# ATSAM4S4A register map
Vendor: Atmel; File version: 0
CPU: CM4 r0p1, selectable endian, no MPU, no FPU, 0x4 interrupt priority bits, 0x0 interrupts
Registers are 32-bit, read-write, reset 0x0 unless marked. A register's access mark holds for its fields unless they carry their own. Offsets are from the block's base; [hi:lo] are bit positions; {n}, {i} and the like mark numbered series; 'fields as' and 'values as' point back to an identical list.

## PWM — Pulse Width Modulation Controller
Base 0x40020000; register names take the prefix PWM_
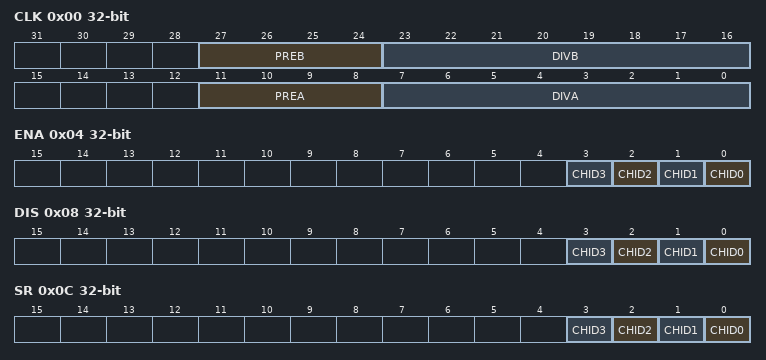
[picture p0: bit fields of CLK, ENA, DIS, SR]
0x00 CLK — PWM Clock Register
  [27:24] PREB — CLKB Source Clock Selection
    0=CLK (Peripheral clock); 1=CLK_DIV2 (Peripheral clock/2); 2=CLK_DIV4 (Peripheral clock/4); 3=CLK_DIV8 (Peripheral clock/8); 4=CLK_DIV16 (Peripheral clock/16); 5=CLK_DIV32 (Peripheral clock/32); 6=CLK_DIV64 (Peripheral clock/64); 7=CLK_DIV128 (Peripheral clock/128); 8=CLK_DIV256 (Peripheral clock/256); 9=CLK_DIV512 (Peripheral clock/512); 10=CLK_DIV1024 (Peripheral clock/1024)
  [23:16] DIVB — CLKB Divide Factor
    0=CLKB_POFF (CLKB clock is turned off); 1=PREB (CLKB clock is clock selected by PREB)
  [11:8] PREA — CLKA Source Clock Selection
    values as PREB
  [7:0] DIVA — CLKA Divide Factor
    0=CLKA_POFF (CLKA clock is turned off); 1=PREA (CLKA clock is clock selected by PREA)
0x04 ENA wo reset not defined — PWM Enable Register
  [n] CHID{n} (n=0..3) — Channel ID
0x08 DIS wo reset not defined — PWM Disable Register
  [n] CHID{n} (n=0..3) — Channel ID
0x0C SR ro — PWM Status Register
  [n] CHID{n} (n=0..3) — Channel ID
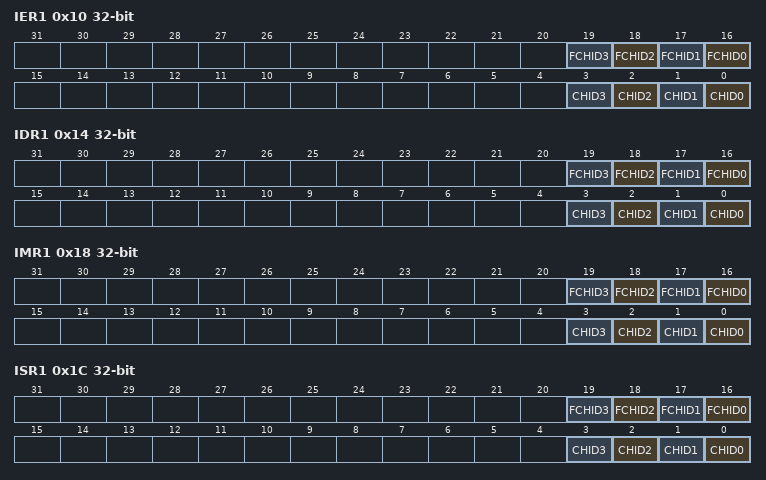
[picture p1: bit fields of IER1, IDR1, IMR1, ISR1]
0x10 IER1 wo reset not defined — PWM Interrupt Enable Register 1
  [n+16] FCHID{n} (n=0..3) — Fault Protection Trigger on Channel {n} Interrupt Enable
  [n] CHID{n} (n=0..3) — Counter Event on Channel {n} Interrupt Enable
0x14 IDR1 wo reset not defined — PWM Interrupt Disable Register 1
  [n+16] FCHID{n} (n=0..3) — Fault Protection Trigger on Channel {n} Interrupt Disable
  [n] CHID{n} (n=0..3) — Counter Event on Channel {n} Interrupt Disable
0x18 IMR1 ro — PWM Interrupt Mask Register 1
  [n+16] FCHID{n} (n=0..3) — Fault Protection Trigger on Channel {n} Interrupt Mask
  [n] CHID{n} (n=0..3) — Counter Event on Channel {n} Interrupt Mask
0x1C ISR1 ro — PWM Interrupt Status Register 1
  [n+16] FCHID{n} (n=0..3) — Fault Protection Trigger on Channel {n}
  [n] CHID{n} (n=0..3) — Counter Event on Channel {n}
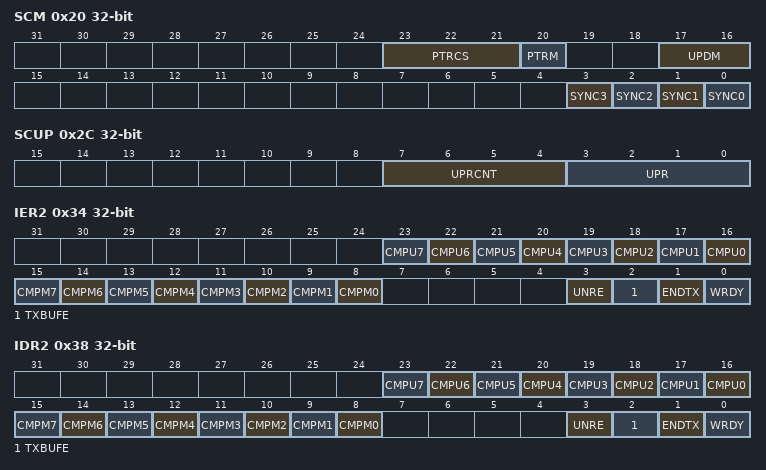
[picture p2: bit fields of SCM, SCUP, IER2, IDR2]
0x20 SCM — PWM Sync Channels Mode Register
  [23:21] PTRCS — Peripheral DMA Controller Transfer Request Comparison Selection
  [20] PTRM — Peripheral DMA Controller Transfer Request Mode
  [17:16] UPDM — Synchronous Channels Update Mode
    0=MODE0 (Manual write of double buffer registers and manual update of synchronous channels); 1=MODE1 (Manual write of double buffer registers and automatic update of synchronous channels); 2=MODE2 (Automatic write of duty-cycle update registers by the Peripheral DMA Controller and automatic update of synchronous channels)
  [n] SYNC{n} (n=0..3) — Synchronous Channel {n}
0x28 SCUC — PWM Sync Channels Update Control Register
  [0] UPDULOCK — Synchronous Channels Update Unlock
0x2C SCUP — PWM Sync Channels Update Period Register
  [7:4] UPRCNT — Update Period Counter
  [3:0] UPR — Update Period
0x30 SCUPUPD wo reset not defined — PWM Sync Channels Update Period Update Register
  [3:0] UPRUPD — Update Period Update
0x34 IER2 wo reset not defined — PWM Interrupt Enable Register 2
  [n+16] CMPU{n} (n=0..7) — Comparison {n} Update Interrupt Enable
  [n+8] CMPM{n} (n=0..7) — Comparison {n} Match Interrupt Enable
  [3] UNRE — Synchronous Channels Update Underrun Error Interrupt Enable
  [2] TXBUFE — PDC TX Buffer Empty Interrupt Enable
  [1] ENDTX — PDC End of TX Buffer Interrupt Enable
  [0] WRDY — Write Ready for Synchronous Channels Update Interrupt Enable
0x38 IDR2 wo reset not defined — PWM Interrupt Disable Register 2
  [n+16] CMPU{n} (n=0..7) — Comparison {n} Update Interrupt Disable
  [n+8] CMPM{n} (n=0..7) — Comparison {n} Match Interrupt Disable
  [3] UNRE — Synchronous Channels Update Underrun Error Interrupt Disable
  [2] TXBUFE — PDC TX Buffer Empty Interrupt Disable
  [1] ENDTX — PDC End of TX Buffer Interrupt Disable
  [0] WRDY — Write Ready for Synchronous Channels Update Interrupt Disable
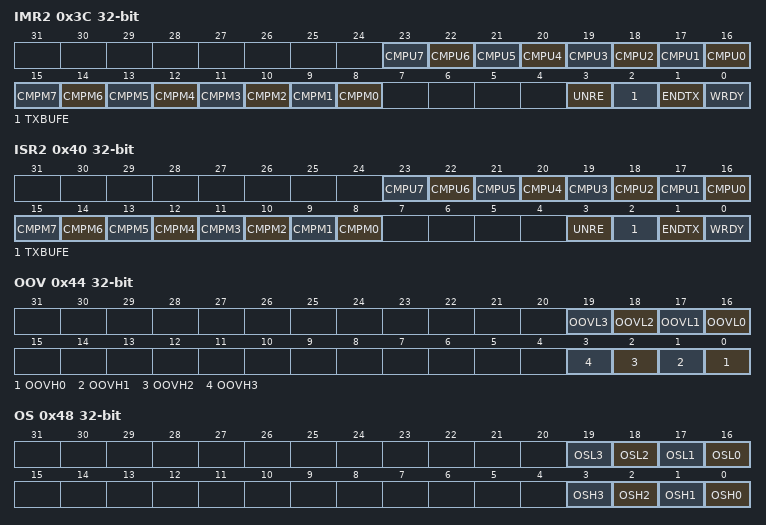
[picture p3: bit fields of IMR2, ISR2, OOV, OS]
0x3C IMR2 ro — PWM Interrupt Mask Register 2
  [n+16] CMPU{n} (n=0..7) — Comparison {n} Update Interrupt Mask
  [n+8] CMPM{n} (n=0..7) — Comparison {n} Match Interrupt Mask
  [3] UNRE — Synchronous Channels Update Underrun Error Interrupt Mask
  [2] TXBUFE — PDC TX Buffer Empty Interrupt Mask
  [1] ENDTX — PDC End of TX Buffer Interrupt Mask
  [0] WRDY — Write Ready for Synchronous Channels Update Interrupt Mask
0x40 ISR2 ro — PWM Interrupt Status Register 2
  [n+16] CMPU{n} (n=0..7) — Comparison {n} Update
  [n+8] CMPM{n} (n=0..7) — Comparison {n} Match
  [3] UNRE — Synchronous Channels Update Underrun Error
  [2] TXBUFE — PDC TX Buffer Empty
  [1] ENDTX — PDC End of TX Buffer
  [0] WRDY — Write Ready for Synchronous Channels Update
0x44 OOV — PWM Output Override Value Register
  [n+16] OOVL{n} (n=0..3) — Output Override Value for PWML output of the channel {n}
  [n] OOVH{n} (n=0..3) — Output Override Value for PWMH output of the channel {n}
0x48 OS — PWM Output Selection Register
  [n+16] OSL{n} (n=0..3) — Output Selection for PWML output of the channel {n}
  [n] OSH{n} (n=0..3) — Output Selection for PWMH output of the channel {n}
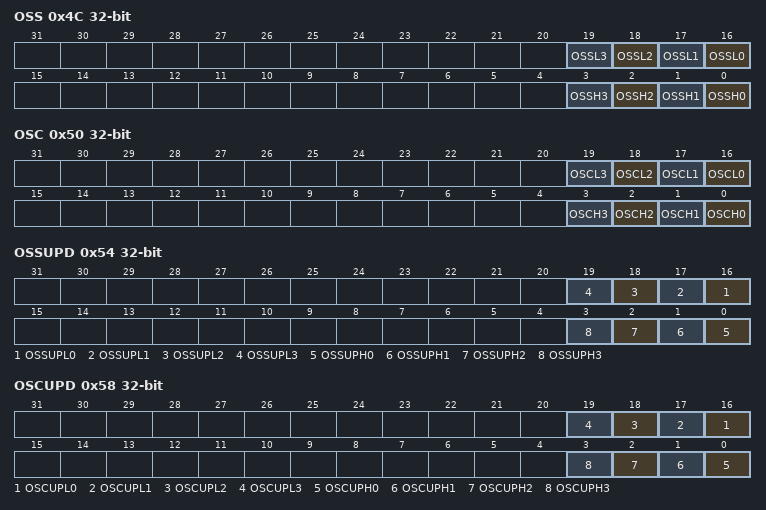
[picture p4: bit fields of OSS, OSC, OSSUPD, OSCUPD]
0x4C OSS wo reset not defined — PWM Output Selection Set Register
  [n+16] OSSL{n} (n=0..3) — Output Selection Set for PWML output of the channel {n}
  [n] OSSH{n} (n=0..3) — Output Selection Set for PWMH output of the channel {n}
0x50 OSC wo reset not defined — PWM Output Selection Clear Register
  [n+16] OSCL{n} (n=0..3) — Output Selection Clear for PWML output of the channel {n}
  [n] OSCH{n} (n=0..3) — Output Selection Clear for PWMH output of the channel {n}
0x54 OSSUPD wo reset not defined — PWM Output Selection Set Update Register
  [n+16] OSSUPL{n} (n=0..3) — Output Selection Set for PWML output of the channel {n}
  [n] OSSUPH{n} (n=0..3) — Output Selection Set for PWMH output of the channel {n}
0x58 OSCUPD wo reset not defined — PWM Output Selection Clear Update Register
  [n+16] OSCUPL{n} (n=0..3) — Output Selection Clear for PWML output of the channel {n}
  [n] OSCUPH{n} (n=0..3) — Output Selection Clear for PWMH output of the channel {n}
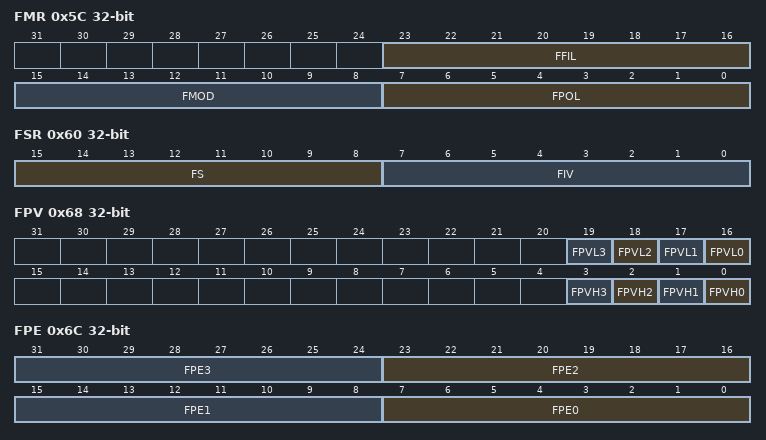
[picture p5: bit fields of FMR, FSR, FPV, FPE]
0x5C FMR — PWM Fault Mode Register
  [23:16] FFIL — Fault Filtering
  [15:8] FMOD — Fault Activation Mode
  [7:0] FPOL — Fault Polarity
0x60 FSR ro — PWM Fault Status Register
  [15:8] FS — Fault Status
  [7:0] FIV — Fault Input Value
0x64 FCR wo reset not defined — PWM Fault Clear Register
  [7:0] FCLR — Fault Clear
0x68 FPV — PWM Fault Protection Value Register
  [n+16] FPVL{n} (n=0..3) — Fault Protection Value for PWML output on channel {n}
  [n] FPVH{n} (n=0..3) — Fault Protection Value for PWMH output on channel {n}
0x6C FPE — PWM Fault Protection Enable Register
  [8n+7:8n] FPE{n} (n=0..3) — Fault Protection Enable for channel {n}
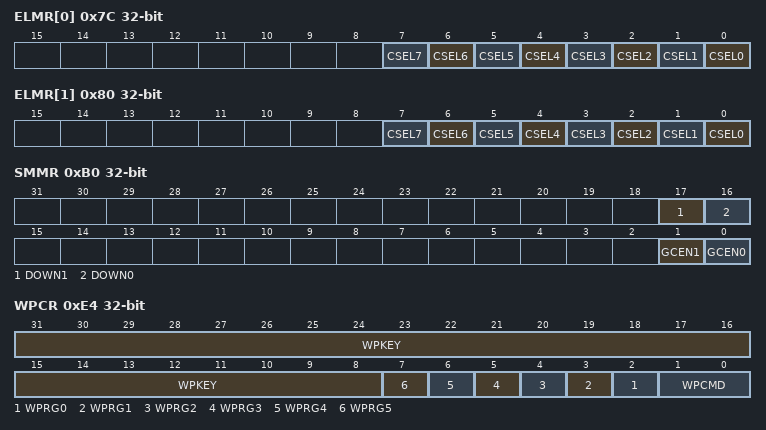
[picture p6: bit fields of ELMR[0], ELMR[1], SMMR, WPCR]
0x7C ELMR[0] reset not defined — PWM Event Line 0 Mode Register
  [n] CSEL{n} (n=0..7) — Comparison {n} Selection
0x80 ELMR[1] reset not defined — PWM Event Line 0 Mode Register
  [n] CSEL{n} (n=0..7) — Comparison {n} Selection
0xB0 SMMR — PWM Stepper Motor Mode Register
  [17] DOWN1 — DOWN Count
  [16] DOWN0 — DOWN Count
  [1] GCEN1 — Gray Count ENable
  [0] GCEN0 — Gray Count ENable
0xE4 WPCR wo reset not defined — PWM Write Protection Control Register
  [31:8] WPKEY — Write Protection Key
    0x50574D=PASSWD (Writing any other value in this field aborts the write operation of the WPCMD field.Always reads as 0)
  [n+2] WPRG{n} (n=0..5) — Write Protection Register Group {n}
  [1:0] WPCMD — Write Protection Command
    0=DISABLE_SW_PROT (Disables the software write protection of the register groups of which the bit WPRGx is at '1'.); 1=ENABLE_SW_PROT (Enables the software write protection of the register groups of which the bit WPRGx is at '1'.); 2=ENABLE_HW_PROT (Enables the hardware write protection of the register groups of which the bit WPRGx is at '1'. Only a hardware reset of the PWM controller can disable the hardware write protection. Moreover, to meet security requirements, the PIO lines associated with the PWM can not be configured through the PIO interface.)
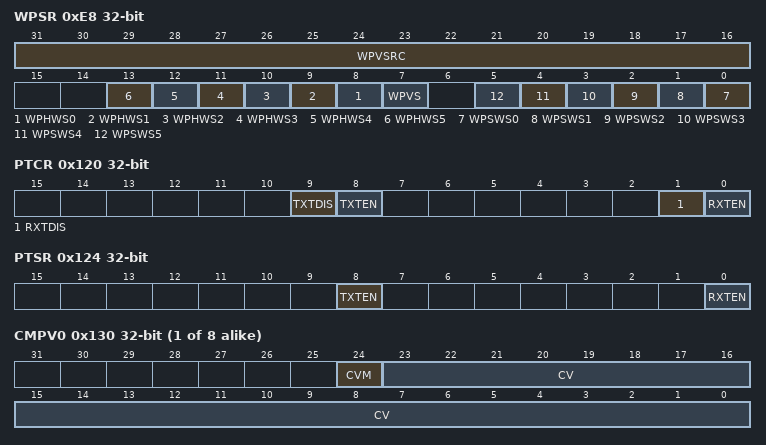
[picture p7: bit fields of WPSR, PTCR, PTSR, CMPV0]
0xE8 WPSR ro — PWM Write Protection Status Register
  [31:16] WPVSRC — Write Protect Violation Source
  [n+8] WPHWS{n} (n=0..5) — Write Protect HW Status
  [7] WPVS — Write Protect Violation Status
  [n] WPSWS{n} (n=0..5) — Write Protect SW Status
0x108 TPR — Transmit Pointer Register
  [31:0] TXPTR — Transmit Counter Register
0x10C TCR — Transmit Counter Register
  [15:0] TXCTR
0x118 TNPR — Transmit Next Pointer Register
  [31:0] TXNPTR — Transmit Next Pointer
0x11C TNCR — Transmit Next Counter Register
  [15:0] TXNCTR — Transmit Counter Next
0x120 PTCR wo reset not defined — Transfer Control Register
  [9] TXTDIS — Transmitter Transfer Disable
  [8] TXTEN — Transmitter Transfer Enable
  [1] RXTDIS — Receiver Transfer Disable
  [0] RXTEN — Receiver Transfer Enable
0x124 PTSR ro — Transfer Status Register
  [8] TXTEN — Transmitter Transfer Enable
  [0] RXTEN — Receiver Transfer Enable
{0x130+0x10*i} CMPV{i} (i=0..7) — PWM Comparison {i} Value Register
  [24] CVM — Comparison x Value Mode
  [23:0] CV — Comparison x Value
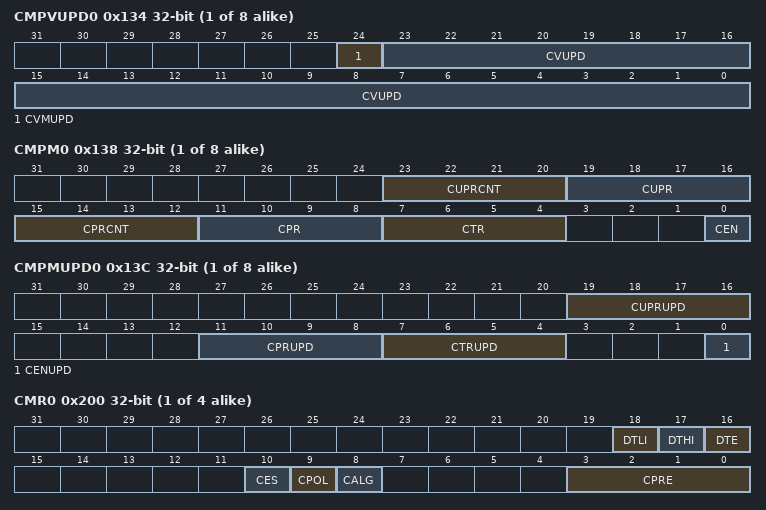
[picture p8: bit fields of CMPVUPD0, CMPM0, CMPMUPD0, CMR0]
{0x134+0x10*i} CMPVUPD{i} wo reset not defined (i=0..7) — PWM Comparison {i} Value Update Register
  [24] CVMUPD — Comparison x Value Mode Update
  [23:0] CVUPD — Comparison x Value Update
{0x138+0x10*i} CMPM{i} (i=0..7) — PWM Comparison {i} Mode Register
  [23:20] CUPRCNT — Comparison x Update Period Counter
  [19:16] CUPR — Comparison x Update Period
  [15:12] CPRCNT — Comparison x Period Counter
  [11:8] CPR — Comparison x Period
  [7:4] CTR — Comparison x Trigger
  [0] CEN — Comparison x Enable
{0x13C+0x10*i} CMPMUPD{i} wo reset not defined (i=0..7) — PWM Comparison {i} Mode Update Register
  [19:16] CUPRUPD — Comparison x Update Period Update
  [11:8] CPRUPD — Comparison x Period Update
  [7:4] CTRUPD — Comparison x Trigger Update
  [0] CENUPD — Comparison x Enable Update
{0x200+0x20*i} CMR{i} (i=0..3) — PWM Channel Mode Register (ch_num = {i})
  [18] DTLI — Dead-Time PWMLx Output Inverted
  [17] DTHI — Dead-Time PWMHx Output Inverted
  [16] DTE — Dead-Time Generator Enable
  [10] CES — Counter Event Selection
  [9] CPOL — Channel Polarity
  [8] CALG — Channel Alignment
  [3:0] CPRE — Channel Pre-scaler
    0=MCK (Peripheral clock); 1=MCK_DIV_2 (Peripheral clock/2); 2=MCK_DIV_4 (Peripheral clock/4); 3=MCK_DIV_8 (Peripheral clock/8); 4=MCK_DIV_16 (Peripheral clock/16); 5=MCK_DIV_32 (Peripheral clock/32); 6=MCK_DIV_64 (Peripheral clock/64); 7=MCK_DIV_128 (Peripheral clock/128); 8=MCK_DIV_256 (Peripheral clock/256); 9=MCK_DIV_512 (Peripheral clock/512); 10=MCK_DIV_1024 (Peripheral clock/1024); 11=CLKA (Clock A); 12=CLKB (Clock B)
{0x204+0x20*i} CDTY{i} (i=0..3) — PWM Channel Duty Cycle Register (ch_num = {i})
  [23:0] CDTY — Channel Duty-Cycle
{0x208+0x20*i} CDTYUPD{i} wo reset not defined (i=0..3) — PWM Channel Duty Cycle Update Register (ch_num = {i})
  [23:0] CDTYUPD — Channel Duty-Cycle Update
{0x20C+0x20*i} CPRD{i} (i=0..3) — PWM Channel Period Register (ch_num = {i})
  [23:0] CPRD — Channel Period
{0x210+0x20*i} CPRDUPD{i} wo reset not defined (i=0..3) — PWM Channel Period Update Register (ch_num = {i})
  [23:0] CPRDUPD — Channel Period Update
{0x214+0x20*i} CCNT{i} ro (i=0..3) — PWM Channel Counter Register (ch_num = {i})
  [23:0] CNT — Channel Counter Register
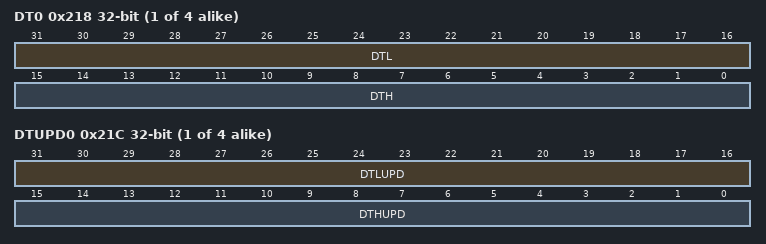
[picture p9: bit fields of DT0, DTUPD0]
{0x218+0x20*i} DT{i} (i=0..3) — PWM Channel Dead Time Register (ch_num = {i})
  [31:16] DTL — Dead-Time Value for PWMLx Output
  [15:0] DTH — Dead-Time Value for PWMHx Output
{0x21C+0x20*i} DTUPD{i} wo reset not defined (i=0..3) — PWM Channel Dead Time Update Register (ch_num = {i})
  [31:16] DTLUPD — Dead-Time Value Update for PWMLx Output
  [15:0] DTHUPD — Dead-Time Value Update for PWMHx Output
